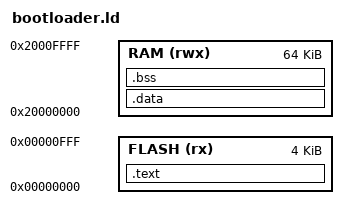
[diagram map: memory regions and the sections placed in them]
MEMORY
{
    FLASH (rx) : ORIGIN = 0x00000000, LENGTH = 0x00001000
    RAM (rwx) : ORIGIN = 0x20000000, LENGTH = 0x00010000
}

SECTIONS
{
    .text :
    {
        _start_text = .;
        KEEP(*(.isr_vector))
        . = 0x400;
        KEEP(*(.utils))
        KEEP(*(.text*))
        *(.rodata*)
        . = ALIGN(4);
        _end_text = .;
    } > FLASH

    _stored_data = .;

    .data : AT (_stored_data)
    {
        _start_data = .;
        KEEP(*(.data*))
        . = ALIGN(4);
        _end_data = .;
    } > RAM

    .bss (NOLOAD) : 
    {
        _start_bss = .;
        *(.bss*)
        *(COMMON)
        . = ALIGN(4);
        _end_bss = .;
        _end = .;
    } > RAM
    . = ALIGN(4);
}

END_STACK = ORIGIN(RAM) + LENGTH(RAM);
